# STM32G0C1xx register map
File version: 1.0
Registers are 32-bit, read-write, reset 0x0 unless marked. A register's access mark holds for its fields unless they carry their own. Offsets are from the block's base; [hi:lo] are bit positions; {n}, {i} and the like mark numbered series.

## EXTI — Asynch Interrupt/Event Controller (EXTI)
Base 0x40021800
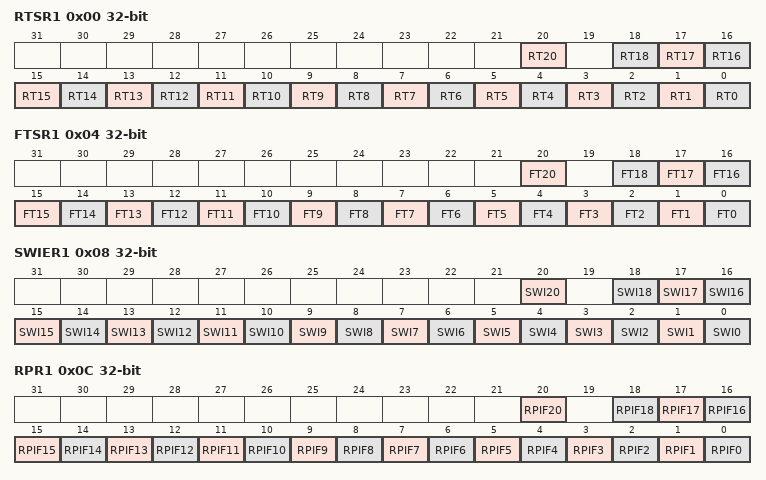
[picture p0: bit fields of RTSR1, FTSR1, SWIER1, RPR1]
0x00 RTSR1 — EXTI Rising Trigger Selection Register 1
  [20] RT20 — Rising trigger configuration for input line 20
  [n] RT{n} (n=0..18) — Rising trigger configuration for input line {n}
0x04 FTSR1 — EXTI Falling Trigger Selection Register 1
  [20] FT20 — Falling trigger configuration for input line 20
  [n] FT{n} (n=0..18) — Falling trigger configuration for input line {n}
0x08 SWIER1 — EXTI Software Interrupt event Register 1
  [20] SWI20 — Software Interrupt on line 20
  [n] SWI{n} (n=0..18) — Software Interrupt on line {n}
0x0C RPR1 — EXTI Rising Pending Register 1
  [20] RPIF20 — Rising Pending Interrupt Flag on line 20
  [n] RPIF{n} (n=0..18) — Rising Pending Interrupt Flag on line {n}
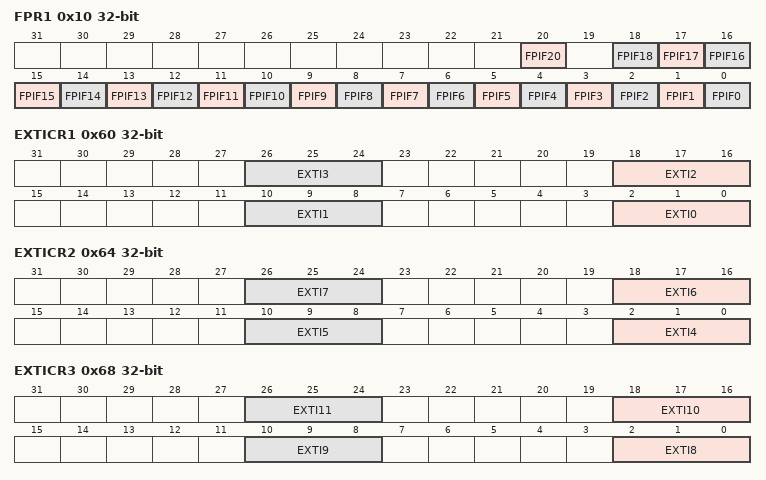
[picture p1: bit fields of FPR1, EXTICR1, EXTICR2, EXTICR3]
0x10 FPR1 — EXTI Falling Pending Register 1
  [20] FPIF20 — Falling Pending Interrupt Flag on line 20
  [n] FPIF{n} (n=0..18) — Falling Pending Interrupt Flag on line {n}
0x20 RTSR2 — EXTI Rising Trigger Selection Register 2
  [2] RT34 — Rising trigger configuration for input line 34
0x24 FTSR2 — EXTI Falling Trigger Selection Register 2
  [2] FT34 — Falling trigger configuration for input line 34
0x28 SWIER2 — EXTI Software Interrupt event Register 2
  [2] SWI34 — Software Interrupt on line 34
0x2C RPR2 — EXTI Rising Pending Register 2
  [2] RPIF34 — Rising Pending Interrupt Flag on line 34
0x30 FPR2 — EXTI Falling Pending Register 2
  [2] RPIF34 — Rising Pending Interrupt Flag on line 34
0x60 EXTICR1 — EXTI External Interrupt Configuration Register, 0x60 -- 0x6C
  [8n+2:8n] EXTI{n} (n=0..3) — EXTI {n} configuration
0x64 EXTICR2 — EXTI External Interrupt Configuration Register, 0x60 -- 0x6C
  [8n-30:8n-32] EXTI{n} (n=4..7) — EXTI {n} configuration
0x68 EXTICR3 — EXTI External Interrupt Configuration Register, 0x60 -- 0x6C
  [8n-62:8n-64] EXTI{n} (n=8..11) — EXTI {n} configuration
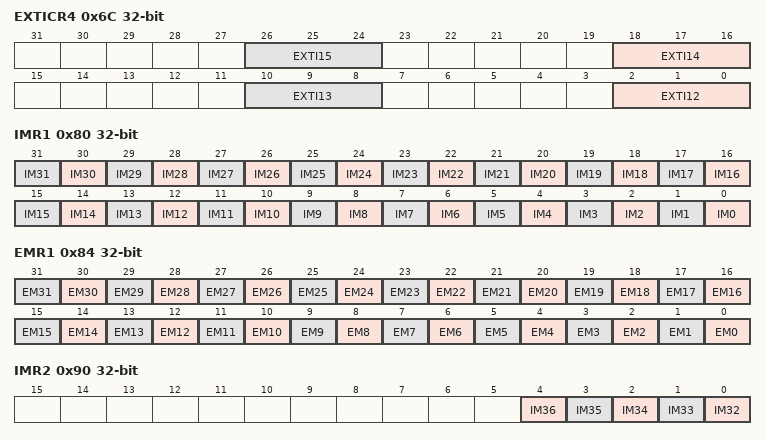
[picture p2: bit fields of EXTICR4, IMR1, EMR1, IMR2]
0x6C EXTICR4 — EXTI External Interrupt Configuration Register, 0x60 -- 0x6C
  [8n-94:8n-96] EXTI{n} (n=12..15) — EXTI {n} configuration
0x80 IMR1 — EXTI Interrupt Mask Register 1
  [n] IM{n} (n=0..31) — Interrupt Mask on line {n}
0x84 EMR1 — EXTI Event Mask Register 1
  [n] EM{n} (n=0..31) — Event Mask on line {n}
0x90 IMR2 — EXTI Interrupt Mask Register 2
  [n-32] IM{n} (n=32..36) — Interrupt Mask on line {n}
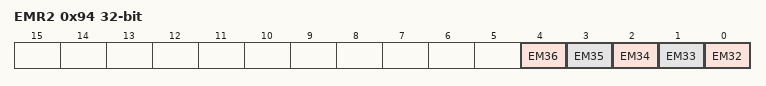
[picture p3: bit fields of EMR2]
0x94 EMR2 — EXTI Event Mask Register 2
  [n-32] EM{n} (n=32..36) — Event Mask on line {n}

## FLASH — FLASH Registers
Base 0x40022000
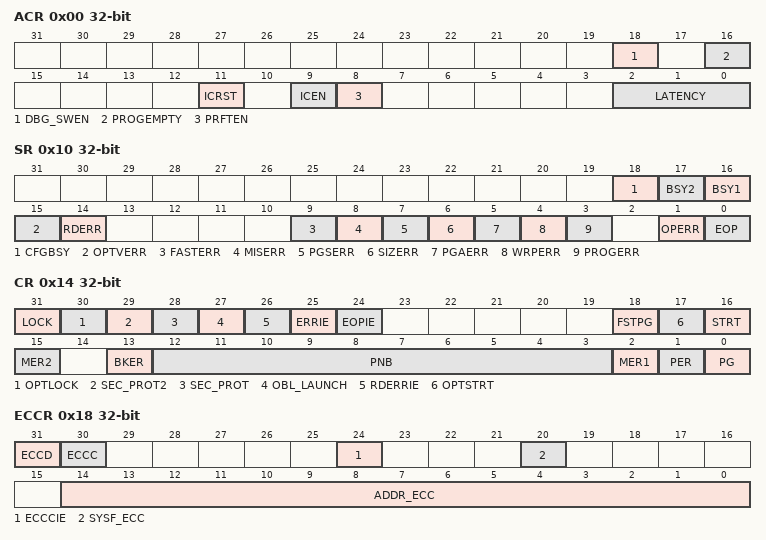
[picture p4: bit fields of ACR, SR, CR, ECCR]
0x00 ACR — FLASH Access Control register
  [18] DBG_SWEN
  [16] PROGEMPTY
  [11] ICRST
  [9] ICEN
  [8] PRFTEN
  [2:0] LATENCY
    0=FLASH Zero Latency cycle; 1=FLASH One Latency cycle; 2=FLASH Two wait states
0x08 KEYR — FLASH Key register
0x0C OPTKEYR — FLASH Option Key register
0x10 SR — FLASH Status register
  [18] CFGBSY, [17] BSY2, [16] BSY1, [15] OPTVERR, [14] RDERR, [9] FASTERR, [8] MISERR, [7] PGSERR, [6] SIZERR, [5] PGAERR, [4] WRPERR, [3] PROGERR, [1] OPERR, [0] EOP
0x14 CR — FLASH Control register
  [31] LOCK, [30] OPTLOCK, [29] SEC_PROT2, [28] SEC_PROT, [27] OBL_LAUNCH, [26] RDERRIE, [25] ERRIE, [24] EOPIE, [18] FSTPG, [17] OPTSTRT, [16] STRT, [15] MER2, [13] BKER, [12:3] PNB, [2] MER1, [1] PER, [0] PG
0x18 ECCR — FLASH ECC bank 1 register
  [31] ECCD, [30] ECCC, [24] ECCCIE, [20] SYSF_ECC, [14:0] ADDR_ECC
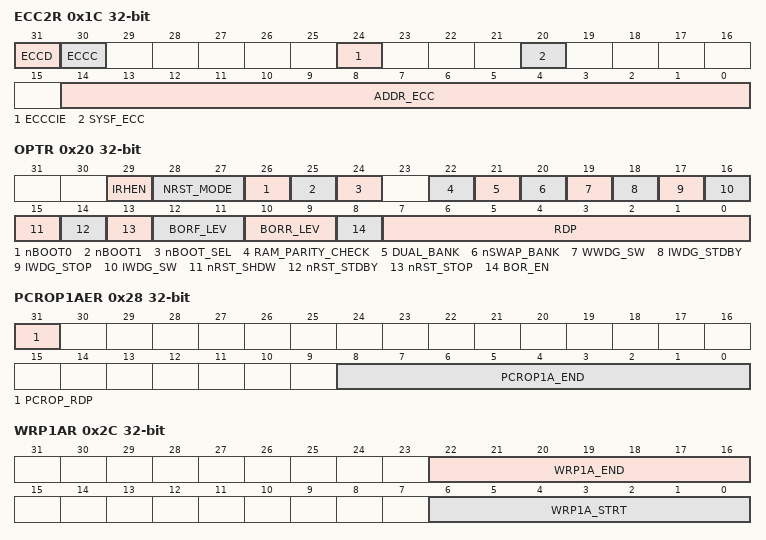
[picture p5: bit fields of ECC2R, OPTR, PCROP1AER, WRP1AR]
0x1C ECC2R — FLASH ECC bank 2 register
  [31] ECCD, [30] ECCC, [24] ECCCIE, [20] SYSF_ECC, [14:0] ADDR_ECC
0x20 OPTR — FLASH Option register
  [29] IRHEN, [28:27] NRST_MODE, [26] nBOOT0, [25] nBOOT1, [24] nBOOT_SEL, [22] RAM_PARITY_CHECK, [21] DUAL_BANK, [20] nSWAP_BANK, [19] WWDG_SW, [18] IWDG_STDBY, [17] IWDG_STOP, [16] IWDG_SW, [15] nRST_SHDW, [14] nRST_STDBY, [13] nRST_STOP, [12:11] BORF_LEV, [10:9] BORR_LEV, [8] BOR_EN, [7:0] RDP
0x24 PCROP1ASR — FLASH Bank PCROP area A Start address register
  [8:0] PCROP1A_STRT
0x28 PCROP1AER — FLASH Bank PCROP area A End address register
  [31] PCROP_RDP, [8:0] PCROP1A_END
0x2C WRP1AR — FLASH Bank WRP area A address register
  [22:16] WRP1A_END, [6:0] WRP1A_STRT
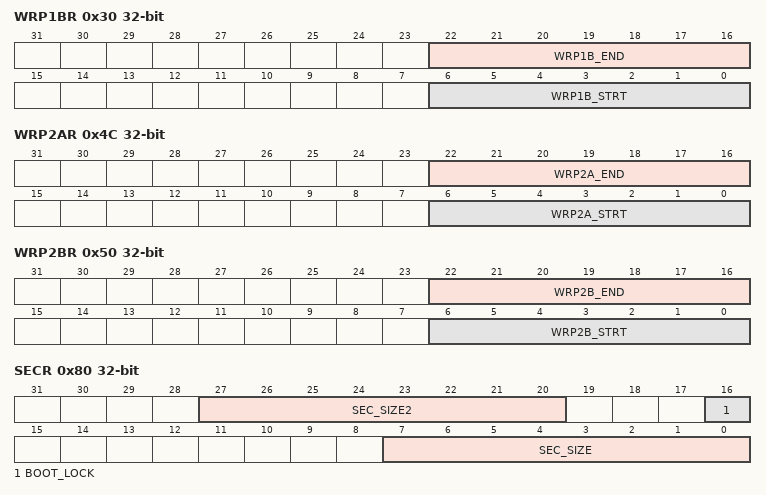
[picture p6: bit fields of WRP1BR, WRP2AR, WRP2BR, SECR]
0x30 WRP1BR — FLASH Bank WRP area B address register
  [22:16] WRP1B_END, [6:0] WRP1B_STRT
0x34 PCROP1BSR — FLASH Bank PCROP area B Start address register
  [8:0] PCROP1B_STRT
0x38 PCROP1BER — FLASH Bank PCROP area B End address register
  [8:0] PCROP1B_END
0x44 PCROP2ASR — FLASH Bank2 PCROP area A Start address register
  [8:0] PCROP2A_STRT
0x48 PCROP2AER — FLASH Bank2 PCROP area A End address register
  [8:0] PCROP2A_END
0x4C WRP2AR — FLASH Bank2 WRP area A address register
  [22:16] WRP2A_END, [6:0] WRP2A_STRT
0x50 WRP2BR — FLASH Bank2 WRP area B address register
  [22:16] WRP2B_END, [6:0] WRP2B_STRT
0x54 PCROP2BSR — FLASH Bank2 PCROP area B Start address register
  [8:0] PCROP2B_STRT
0x58 PCROP2BER — FLASH Bank2 PCROP area B End address register
  [8:0] PCROP2B_END
0x80 SECR — FLASH security register
  [27:20] SEC_SIZE2, [16] BOOT_LOCK, [7:0] SEC_SIZE

## CRC — CRC calculation unit
Base 0x40023000
0x00 DR — CRC Data register
  [31:0] DR — Data register bits
0x04 IDR — CRC Independent data register
  [31:0] IDR — General-purpose 32-bits data register bits
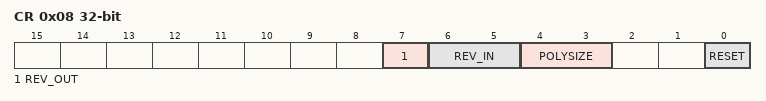
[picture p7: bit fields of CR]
0x08 CR — CRC Control register
  [7] REV_OUT — REV_OUT Reverse Output Data bits
    0=NONE (Output Data bit order not affected); 1=BIT (Output Data bit reversal done by bit)
  [6:5] REV_IN — REV_IN Reverse Input Data bits
    0=NONE (Input Data bit order not affected); 1=BYTE (Input Data bit reversal done by byte); 2=HALFWORD (Input Data bit reversal done by half-word); 3=WORD (Input Data bit reversal done by word)
  [4:3] POLYSIZE — Polynomial size bits
    0=POLYLENGTH_32B (32 bits Polynomial size); 1=POLYLENGTH_16B (16 bits Polynomial size); 2=POLYLENGTH_8B (8 bits Polynomial size); 3=POLYLENGTH_7B (7 bits Polynomial size)
  [0] RESET — RESET the CRC computation unit bit
0x10 INIT — Initial CRC value register
  [31:0] INIT — Initial CRC value bits
0x14 POL — CRC polynomial register
  [31:0] POL — Coefficients of the polynomial

## RNG
Base 0x40025000
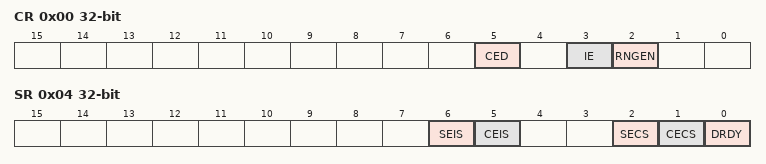
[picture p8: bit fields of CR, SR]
0x00 CR — RNG control register
  [5] CED, [3] IE, [2] RNGEN
0x04 SR — RNG status register
  [6] SEIS, [5] CEIS, [2] SECS, [1] CECS, [0] DRDY
0x08 DR — RNG data register

## AES — AES hardware accelerator
Base 0x40026000
Same registers: AES1 0x40026000 (alternate view of AES)
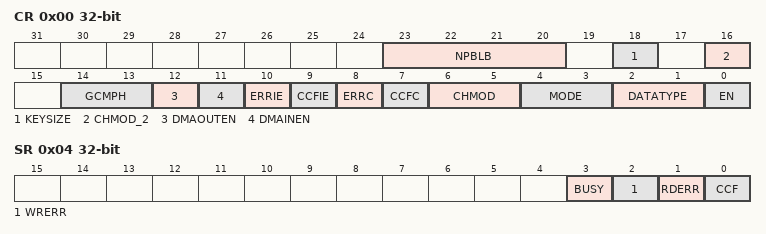
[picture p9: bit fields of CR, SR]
0x00 CR — AES control register
  [23:20] NPBLB — Number of padding bytes in last block of payload
  [18] KEYSIZE — Key size selection
  [16] CHMOD_2 — AES Chaining Mode
  [14:13] GCMPH — GCM Phase
  [12] DMAOUTEN — Enable data output phase DMA management
  [11] DMAINEN — Enable data input phase DMA management
  [10] ERRIE — Error Interrupt Enable
  [9] CCFIE — Computation Complete Flag Interrupt Enable
  [8] ERRC — Error Clear
  [7] CCFC — Computation Complete Flag Clear
  [6:5] CHMOD — AES Chaining Mode
  [4:3] MODE — AES Mode Of Operation
  [2:1] DATATYPE — Data type selection
  [0] EN — AES Enable
0x04 SR — AES status register
  [3] BUSY — Busy Flag
  [2] WRERR — Write Error Flag
  [1] RDERR — Read Error Flag
  [0] CCF — Computation Complete Flag
0x08 DINR — AES data input register
  [31:0] DINR — AES Data Input Register
0x0C DOUTR — AES data output register
  [31:0] DOUTR — AES Data Output Register
{0x10+4i} KEYR{i} (i=0..3) — AES key register {i}
  [31:0] KEYR{i} — AES Key Register {i}
{0x20+4i} IVR{i} (i=0..3) — AES initialization vector register {i}
  [31:0] IVR{i} — AES Initialization Vector Register {i}
{0x20+4i} KEYR{i} (i=4..7) — AES key register {i}
  [31:0] KEYR{i} — AES Key Register {i}
{0x40+4i} SUSP{i}R (i=0..7) — AES Suspend register {i}
  [31:0] SUSP{i}R — AES Suspend registers {i}

## GPIOA — General Purpose I/O
Base 0x50000000
Same registers: GPIOB 0x50000400, GPIOC 0x50000800, GPIOD 0x50000C00, GPIOE 0x50001000, GPIOF 0x50001400
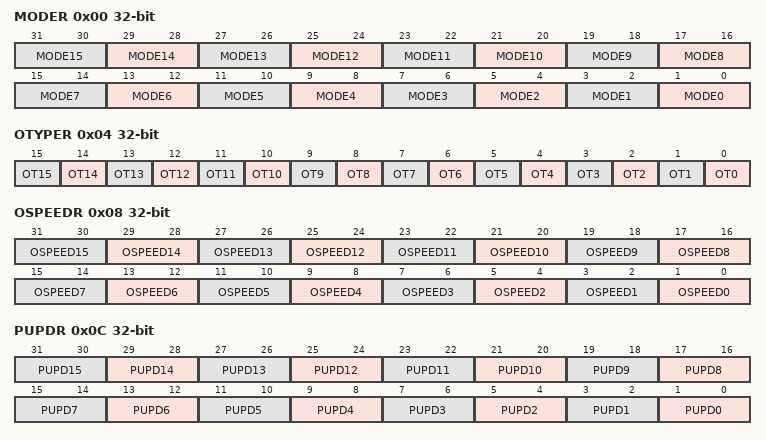
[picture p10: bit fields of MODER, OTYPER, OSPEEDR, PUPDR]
0x00 MODER — GPIO port mode register
  [2n+1:2n] MODE{n} (n=0..15)
0x04 OTYPER — GPIO port output type register
  [n] OT{n} (n=0..15)
0x08 OSPEEDR — GPIO port output speed register
  [2n+1:2n] OSPEED{n} (n=0..15)
0x0C PUPDR — GPIO port pull-up/pull-down register
  [2n+1:2n] PUPD{n} (n=0..15)
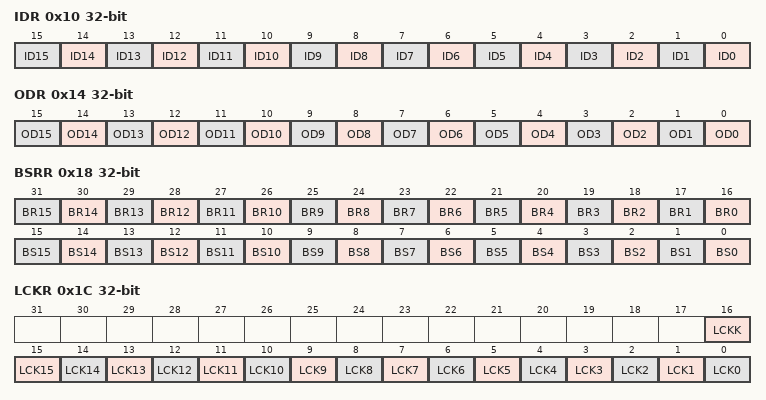
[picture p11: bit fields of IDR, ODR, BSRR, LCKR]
0x10 IDR — GPIO port input data register
  [n] ID{n} (n=0..15)
0x14 ODR — GPIO port output data register
  [n] OD{n} (n=0..15)
0x18 BSRR — GPIO port bit set/reset register
  [n+16] BR{n} (n=0..15), [n] BS{n} (n=0..15)
0x1C LCKR — GPIO port configuration lock register
  [16] LCKK, [n] LCK{n} (n=0..15)
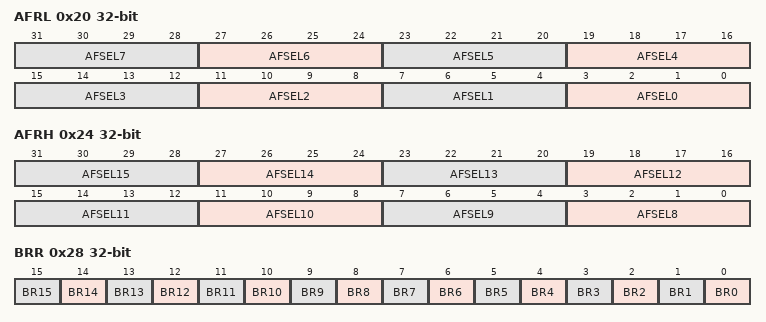
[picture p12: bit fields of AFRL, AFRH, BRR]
0x20 AFRL — GPIO alternate function registers
  [4n+3:4n] AFSEL{n} (n=0..7)
0x24 AFRH — GPIO alternate function registers
  [4n-29:4n-32] AFSEL{n} (n=8..15)
0x28 BRR — GPIO Bit Reset register
  [n] BR{n} (n=0..15)
